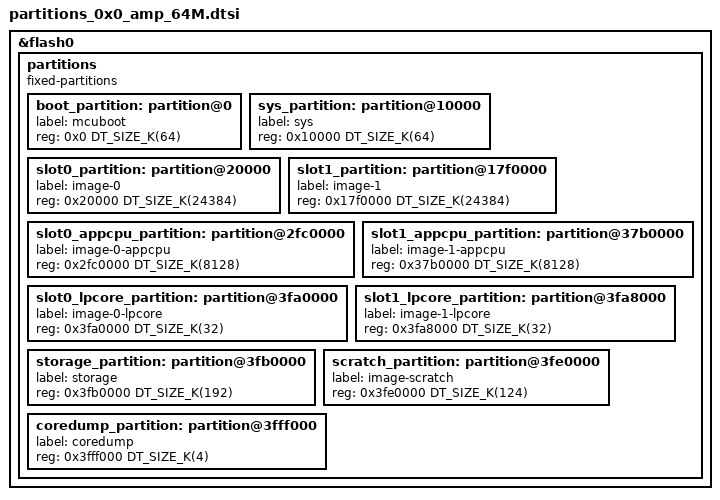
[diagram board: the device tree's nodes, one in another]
/*
 * Copyright (c) 2024-2025 Espressif Systems (Shanghai) Co., Ltd.
 *
 * SPDX-License-Identifier: Apache-2.0
 */

&flash0 {
	partitions {
		compatible = "fixed-partitions";
		#address-cells = <1>;
		#size-cells = <1>;

		boot_partition: partition@0 {
			label = "mcuboot";
			reg = <0x0 DT_SIZE_K(64)>;
		};

		sys_partition: partition@10000 {
			label = "sys";
			reg = <0x10000 DT_SIZE_K(64)>;
		};

		slot0_partition: partition@20000 {
			label = "image-0";
			reg = <0x20000 DT_SIZE_K(24384)>;
		};

		slot1_partition: partition@17f0000 {
			label = "image-1";
			reg = <0x17f0000 DT_SIZE_K(24384)>;
		};

		slot0_appcpu_partition: partition@2fc0000 {
			label = "image-0-appcpu";
			reg = <0x2fc0000 DT_SIZE_K(8128)>;
		};

		slot1_appcpu_partition: partition@37b0000 {
			label = "image-1-appcpu";
			reg = <0x37b0000 DT_SIZE_K(8128)>;
		};

		slot0_lpcore_partition: partition@3fa0000 {
			label = "image-0-lpcore";
			reg = <0x3fa0000 DT_SIZE_K(32)>;
		};

		slot1_lpcore_partition: partition@3fa8000 {
			label = "image-1-lpcore";
			reg = <0x3fa8000 DT_SIZE_K(32)>;
		};

		storage_partition: partition@3fb0000 {
			label = "storage";
			reg = <0x3fb0000 DT_SIZE_K(192)>;
		};

		scratch_partition: partition@3fe0000 {
			label = "image-scratch";
			reg = <0x3fe0000 DT_SIZE_K(124)>;
		};

		coredump_partition: partition@3fff000 {
			label = "coredump";
			reg = <0x3fff000 DT_SIZE_K(4)>;
		};
	};
};

/* Remaining flash size is 0kB
 * Last used address is 0x3FFFFFF
 */
